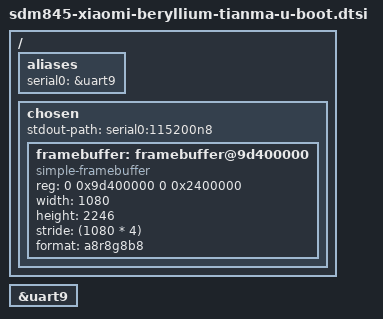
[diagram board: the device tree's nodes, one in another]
// SPDX-License-Identifier: GPL-2.0

/ {
	aliases {
		serial0 = &uart9;
	};

	chosen {
		#address-cells = <2>;
		#size-cells = <2>;
		ranges;

		stdout-path = "serial0:115200n8";

		framebuffer: framebuffer@9d400000 {
			compatible = "simple-framebuffer";
			reg = <0 0x9d400000 0 0x2400000>;
			width = <1080>;
			height = <2246>;
			stride = <(1080 * 4)>;
			format = "a8r8g8b8";
		};
	};
};

&uart9 {
	status = "okay";
};
